# MM32F103xx register map
File version: 1.3
Registers are 32-bit, read-write, reset 0x0 unless marked. A register's access mark holds for its fields unless they carry their own. Offsets are from the block's base; [hi:lo] are bit positions; {n}, {i} and the like mark numbered series.

## EXTI
Base 0x40010400
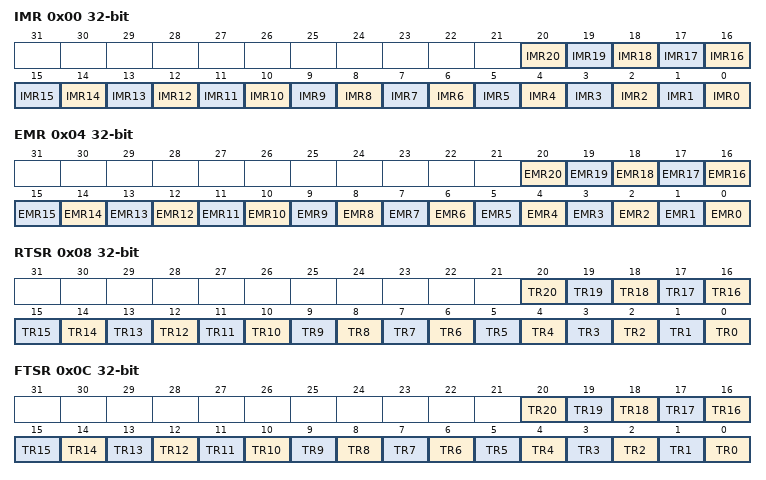
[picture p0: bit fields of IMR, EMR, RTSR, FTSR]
0x00 IMR
  [n] IMR{n} (n=0..20) — Interrupt Mask on line {n}
0x04 EMR
  [n] EMR{n} (n=0..20) — Event Mask on line {n}
0x08 RTSR
  [n] TR{n} (n=0..20) — Rising trigger event configuration bit of line {n}
0x0C FTSR
  [n] TR{n} (n=0..20) — Falling trigger event configuration bit of line {n}
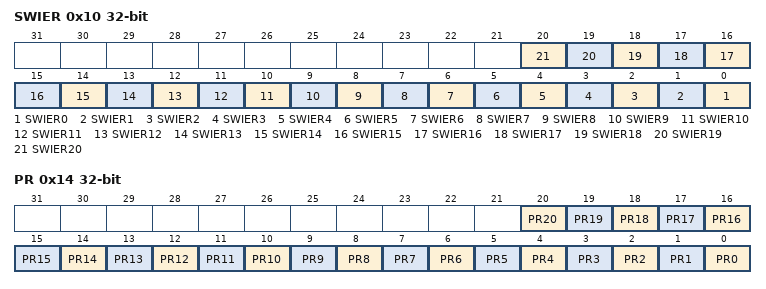
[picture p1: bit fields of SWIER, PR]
0x10 SWIER
  [n] SWIER{n} (n=0..20) — Software interrupt on line {n}
0x14 PR
  [n] PR{n} (n=0..20) — Pending bit

## DMA — DMA controller
Base 0x40020000
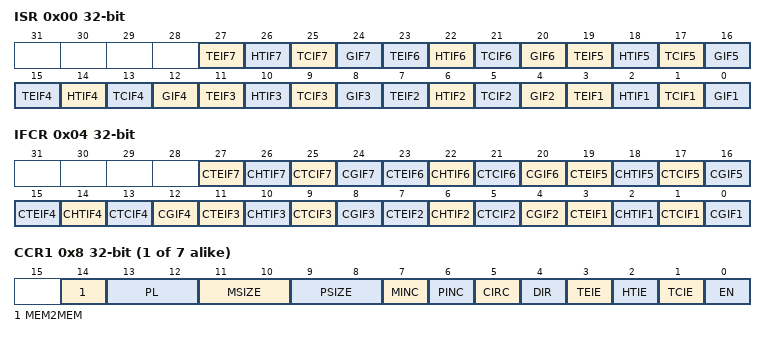
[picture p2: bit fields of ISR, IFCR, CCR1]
0x00 ISR ro
  [4n-1] TEIF{n} (n=1..7) — channel {n} transfer error flag
  [4n-2] HTIF{n} (n=1..7) — channel {n} half transfer flag
  [4n-3] TCIF{n} (n=1..7) — channel {n} half complete flag
  [4n-4] GIF{n} (n=1..7) — channel {n} global interrupt flag
0x04 IFCR ro
  [4n-1] CTEIF{n} (n=1..7) — channel {n} transfer error clear
  [4n-2] CHTIF{n} (n=1..7) — channel {n} half transfer clear
  [4n-3] CTCIF{n} (n=1..7) — channel {n} half complete clear
  [4n-4] CGIF{n} (n=1..7) — channel {n} global interrupt clear
{0x4+4i} CCR{i} (i=1..7)
  [14] MEM2MEM — Memory to memory mode
  [13:12] PL — Channel priority level
  [11:10] MSIZE — Memory size
  [9:8] PSIZE — Peripheral size
  [7] MINC — Memory increment mode
  [6] PINC — Peripheral increment mode
  [5] CIRC — Circular mode
  [4] DIR — Data transfer direction
  [3] TEIE — Transfer error interrupt enable
  [2] HTIE — Half transfer interrupt enable
  [1] TCIE — Transfer complete interrupt enable
  [0] EN — Channel enable
{0x20+4i} CNDTR{i} (i=1..5)
  [15:0] NDT — Number of data to transfer
0x38 CNDTR6 — DMA_CNDTR6
  [15:0] NDT — Number of data to transfer
0x3C CNDTR7
  [15:0] NDT — Number of data to transfer
{0x3C+4i} CPAR{i} (i=1..7)
  [31:0] PA — Peripheral address
{0x5C+4i} CMAR{i} (i=1..7)
  [31:0] MA — Memory address

## BKP — Backup registers
Base 0x40006C00
{0x0+4i} DR{i} (i=1..3)
  [31:0] D — Backup data
0x10 DR4
  [1:0] D — Backup data
{0x0+4i} DR{i} (i=5..10)
  [31:0] D — Backup data
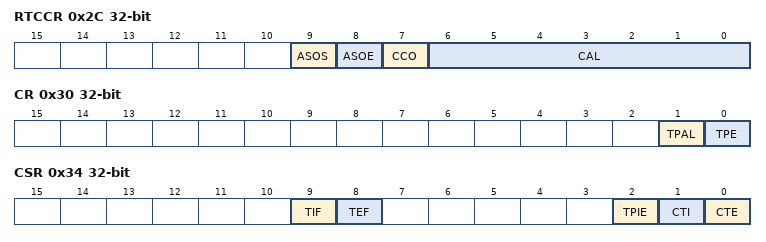
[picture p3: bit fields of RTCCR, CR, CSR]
0x2C RTCCR
  [9] ASOS — Alarm or second output selection
  [8] ASOE — Alarm or second output enable
  [7] CCO — Calibration clock output
  [6:0] CAL — Calibration value
0x30 CR
  [1] TPAL — TAMPER pin active level
  [0] TPE — TAMPER pin enable
0x34 CSR ro
  [9] TIF — Tamper interrupt flag
  [8] TEF — Tamper event flag
  [2] TPIE — TAMPER pin interrupt enable
  [1] CTI — Clear tamper interrupt
  [0] CTE — Clear tamper event

## WWDG — Window watchdog
Base 0x40002C00
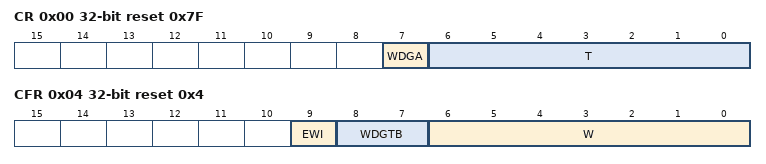
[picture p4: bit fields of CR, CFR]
0x00 CR reset 0x7F
  [7] WDGA — Activation bit
  [6:0] T — 7-bit counter
0x04 CFR reset 0x4
  [9] EWI — Early wakeup interrupt
  [8:7] WDGTB — Timer base
  [6:0] W — 7-bit window value
0x08 SR
  [0] EWIF — Early wakeup interrupt flag

## IWDG — Independent watchdog
Base 0x40003000
0x00 KR wo
  [15:0] KEY — Key value
0x04 PR
  [2:0] PR — Prescaler divider
0x08 RLR
  [11:0] RL — Watchdog counter reload value
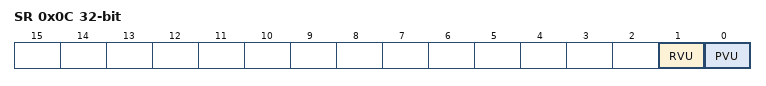
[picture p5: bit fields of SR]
0x0C SR ro
  [1] RVU — Watchdog counter reload value update
  [0] PVU — Watchdog prescaler value update

## TIM2 — General purpose timer
Base 0x40000000
Same registers: TIM3 0x40000400, TIM4 0x40000800
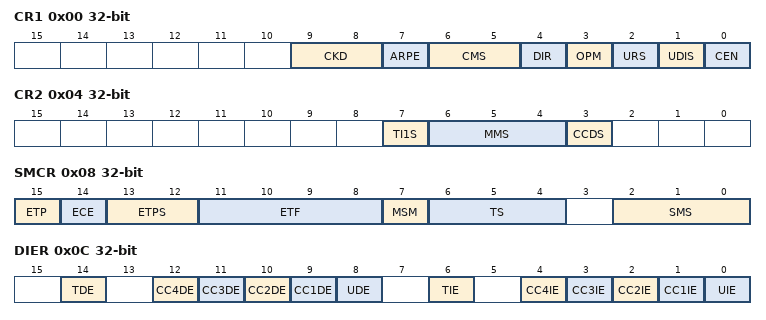
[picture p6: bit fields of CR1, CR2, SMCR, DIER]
0x00 CR1
  [9:8] CKD — Clock division
  [7] ARPE — Auto-reload preload enable
  [6:5] CMS — Center-aligned mode selection
  [4] DIR — Direction
  [3] OPM — One pulse mode
  [2] URS — Update request source
  [1] UDIS — Update disable
  [0] CEN — Counter enable
0x04 CR2
  [7] TI1S — TI1 selection
  [6:4] MMS — Master mode selection
  [3] CCDS — Capture/Compare DMA selection
0x08 SMCR
  [15] ETP — External trigger polarity
  [14] ECE — External clock enable
  [13:12] ETPS — External trigger prescaler
  [11:8] ETF — External trigger filter
  [7] MSM — Master/slave mode
  [6:4] TS — Trigger selection
  [2:0] SMS — Slave mode selection
0x0C DIER
  [14] TDE — Trigger DMA request enable
  [n+8] CC{n}DE (n=1..4) — Capture/Compare {n} DMA request enable
  [8] UDE — Update DMA request enable
  [6] TIE — Trigger interrupt enable
  [n] CC{n}IE (n=1..4) — Capture/Compare {n} interrupt enable
  [0] UIE — Update interrupt enable
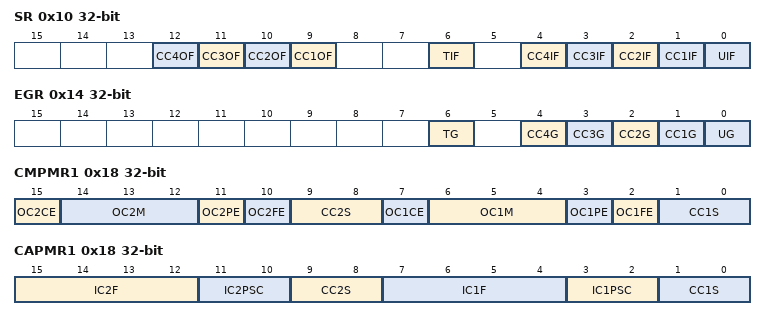
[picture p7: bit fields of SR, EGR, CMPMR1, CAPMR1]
0x10 SR
  [n+8] CC{n}OF (n=1..4) — Capture/Compare {n} overcapture flag
  [6] TIF — Trigger interrupt flag
  [n] CC{n}IF (n=1..4) — Capture/Compare {n} interrupt flag
  [0] UIF — Update interrupt flag
0x14 EGR wo
  [6] TG — Trigger generation
  [n] CC{n}G (n=1..4) — Capture/compare {n} generation
  [0] UG — Update generation
0x18 CMPMR1
  [15] OC2CE — Output compare 2 clear enable
  [14:12] OC2M — Output compare 2 mode
  [11] OC2PE — Output compare 2 preload enable
  [10] OC2FE — Output compare 2 fast enable
  [9:8] CC2S — Capture/Compare 2 selection
  [7] OC1CE — Output compare 1 clear enable
  [6:4] OC1M — Output compare 1 enable
  [3] OC1PE — Output compare 1 preload enable
  [2] OC1FE — Output compare 1 fast enable
  [1:0] CC1S — Capture/Compare 1 selection
0x18 CAPMR1
  [15:12] IC2F — Input capture 2 filter
  [11:10] IC2PSC — input capture 2 prescaler
  [9:8] CC2S — Capture/compare 2 selection
  [7:4] IC1F — Input capture 1 filter
  [3:2] IC1PSC — Input capture 1 prescaler
  [1:0] CC1S — Capture/Compare 1 selection
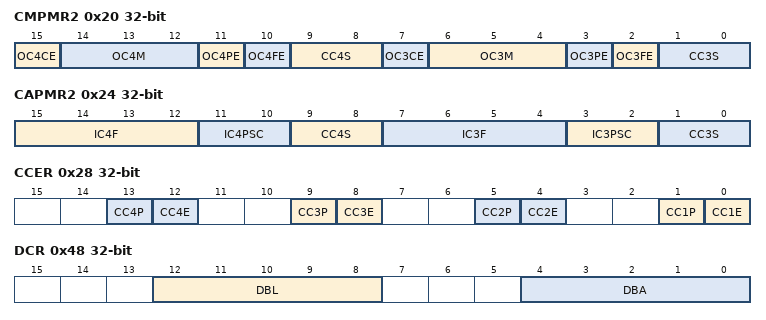
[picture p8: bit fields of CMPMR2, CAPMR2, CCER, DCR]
0x20 CMPMR2
  [15] OC4CE — Output compare 4 clear enable
  [14:12] OC4M — Output compare 4 mode
  [11] OC4PE — Output compare 4 preload enable
  [10] OC4FE — Output compare 4 fast enable
  [9:8] CC4S — Capture/Compare 4 selection
  [7] OC3CE — Output compare 3 clear enable
  [6:4] OC3M — Output compare 3 mode
  [3] OC3PE — Output compare 3 preload enable
  [2] OC3FE — Output compare 3 fast enable
  [1:0] CC3S — Capture/Compare 3 selection
0x24 CAPMR2
  [15:12] IC4F — Input capture 4 filter
  [11:10] IC4PSC — input capture 4 prescaler
  [9:8] CC4S — Capture/compare 4 selection
  [7:4] IC3F — Input capture 3 filter
  [3:2] IC3PSC — Input capture 3 prescaler
  [1:0] CC3S — Capture/Compare 3 selection
0x28 CCER wo
  [4n-3] CC{n}P (n=1..4) — Capture/Compare {n} output polarity
  [4n-4] CC{n}E (n=1..4) — Capture/Compare {n} output enable
0x2C CNT
  [15:0] CNT — Counter value
0x30 PSC
  [15:0] PSC — Prescaler value
0x34 ARR
  [15:0] ARR — Auto reload value
{0x34+4i} CCR{i} (i=1..4)
  [15:0] CCR{i} — Capture/Compare {i} value
0x48 DCR
  [12:8] DBL — DMA burst length
  [4:0] DBA — DMA base address
0x4C DMAR
  [15:0] DMAB — DMA register for burst accesses
